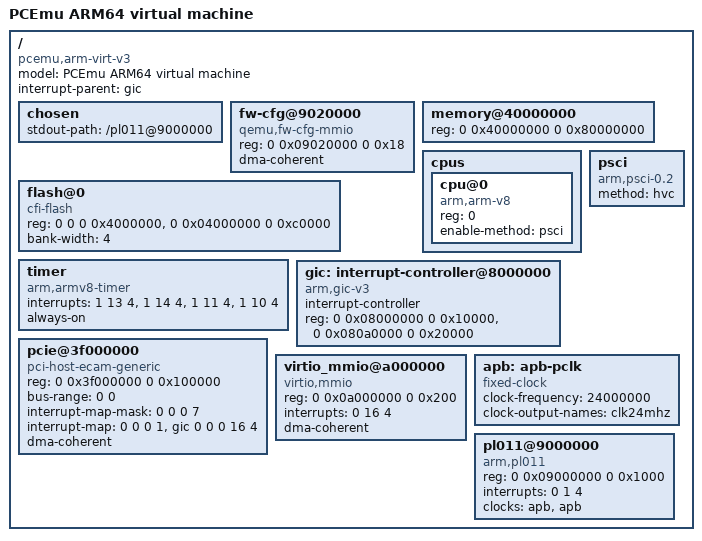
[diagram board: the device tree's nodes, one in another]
/dts-v1/;
/ {
    compatible = "pcemu,arm-virt-v3", "linux,dummy-virt";
    model = "PCEmu ARM64 virtual machine";
    #address-cells = <2>;
    #size-cells = <2>;
    interrupt-parent = <&gic>;
    chosen { stdout-path = "/pl011@9000000"; };
    fw-cfg@9020000 {
        compatible = "qemu,fw-cfg-mmio";
        reg = <0 0x09020000 0 0x18>;
        dma-coherent;
    };
    memory@40000000 { device_type = "memory"; reg = <0 0x40000000 0 0x80000000>; };
    flash@0 {
        compatible = "cfi-flash";
        reg = <0 0 0 0x4000000>, <0 0x04000000 0 0xc0000>;
        bank-width = <4>;
    };
    cpus {
        #address-cells = <1>;
        #size-cells = <0>;
        cpu@0 { device_type = "cpu"; compatible = "arm,arm-v8"; reg = <0>; enable-method = "psci"; };
    };
    psci { compatible = "arm,psci-0.2", "arm,psci"; method = "hvc"; };
    timer {
        compatible = "arm,armv8-timer";
        interrupts = <1 13 4>, <1 14 4>, <1 11 4>, <1 10 4>;
        always-on;
    };
    gic: interrupt-controller@8000000 {
        compatible = "arm,gic-v3";
        #interrupt-cells = <3>;
        #address-cells = <2>;
        #size-cells = <2>;
        interrupt-controller;
        ranges;
        reg = <0 0x08000000 0 0x10000>, <0 0x080a0000 0 0x20000>;
    };
    pcie@3f000000 {
        compatible = "pci-host-ecam-generic";
        device_type = "pci";
        #address-cells = <3>;
        #size-cells = <2>;
        #interrupt-cells = <1>;
        reg = <0 0x3f000000 0 0x100000>;
        bus-range = <0 0>;
        ranges = <0x02000000 0 0x10000000 0 0x10000000 0 0x2f000000>;
        interrupt-map-mask = <0 0 0 7>;
        interrupt-map = <0 0 0 1 &gic 0 0 0 16 4>;
        dma-coherent;
    };
    virtio_mmio@a000000 {
        compatible = "virtio,mmio";
        reg = <0 0x0a000000 0 0x200>;
        interrupts = <0 16 4>;
        dma-coherent;
    };
    apb: apb-pclk { compatible = "fixed-clock"; #clock-cells = <0>; clock-frequency = <24000000>; clock-output-names = "clk24mhz"; };
    pl011@9000000 {
        compatible = "arm,pl011", "arm,primecell";
        reg = <0 0x09000000 0 0x1000>;
        interrupts = <0 1 4>;
        clocks = <&apb>, <&apb>;
        clock-names = "uartclk", "apb_pclk";
    };
};
